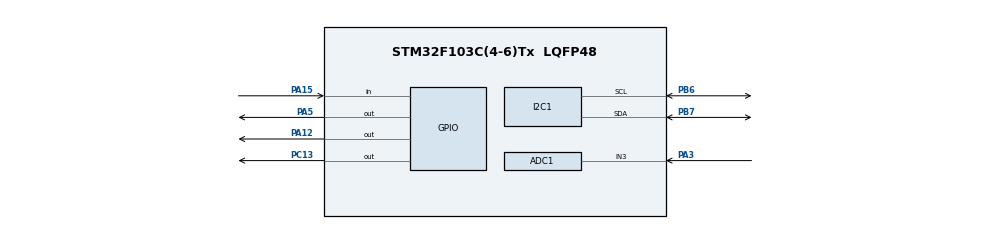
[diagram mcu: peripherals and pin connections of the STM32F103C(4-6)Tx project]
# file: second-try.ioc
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ADC1.Channel-1\#ChannelRegularConversion=ADC_CHANNEL_3
ADC1.NbrOfConversionFlag=1
ADC1.Rank-1\#ChannelRegularConversion=1
ADC1.SamplingTime-1\#ChannelRegularConversion=ADC_SAMPLETIME_1CYCLE_5
ADC1.master=1
Mcu.Family=STM32F1
Mcu.Name=STM32F103C(4-6)Tx
Mcu.Package=LQFP48
NVIC.PriorityGroup=NVIC_PRIORITYGROUP_4
PA12.Signal=GPIO_Output
PA13.Mode=Serial_Wire
PA13.Signal=SYS_JTMS-SWDIO
PA14.Mode=Serial_Wire
PA14.Signal=SYS_JTCK-SWCLK
PA15.Signal=GPIO_Input
PA3.Signal=ADCx_IN3
PA5.Signal=GPIO_Output
PB6.Mode=I2C
PB6.Signal=I2C1_SCL
PB7.Mode=I2C
PB7.Signal=I2C1_SDA
PC13-TAMPER-RTC.Signal=GPIO_Output
ProjectManager.HeapSize=0x200
ProjectManager.StackSize=0x400
ProjectManager.TargetToolchain=MDK-ARM V5.32
RCC.APB1Freq_Value=8000000
RCC.APB2Freq_Value=8000000
SH.ADCx_IN3.0=ADC1_IN3,IN3
TIM2.ClockDivision=TIM_CLOCKDIVISION_DIV1
TIM2.Prescaler=7
VP_TIM2_VS_ClockSourceINT.Mode=Internal
board=custom

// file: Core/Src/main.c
/* USER CODE BEGIN Header */
/**
  ******************************************************************************
  * @file           : main.c
  * @brief          : Main program body
  ******************************************************************************
  * @attention
  *
  * Copyright (c) 2026 STMicroelectronics.
  * All rights reserved.
  *
  * This software is licensed under terms that can be found in the LICENSE file
  * in the root directory of this software component.
  * If no LICENSE file comes with this software, it is provided AS-IS.
  *
  ******************************************************************************
  */
/* USER CODE END Header */
#include "main.h"
#include "oled.h"
#include "dht11.h"
#include "hcsr04.h"
#include <stdio.h>

ADC_HandleTypeDef hadc1;

I2C_HandleTypeDef hi2c1;

TIM_HandleTypeDef htim2;

void SystemClock_Config(void);
static void MX_GPIO_Init(void);
static void MX_I2C1_Init(void);
static void MX_TIM2_Init(void);
static void MX_ADC1_Init(void);

int main(void)
{

  /* MCU Configuration--------------------------------------------------------*/

  /* Reset of all peripherals, Initializes the Flash interface and the Systick. */
  HAL_Init();

  /* Configure the system clock */
  SystemClock_Config();

  /* Initialize all configured peripherals */
  MX_GPIO_Init();
  MX_I2C1_Init();
  MX_TIM2_Init();
  MX_ADC1_Init();
  /* USER CODE BEGIN 2 */
	HAL_TIM_Base_Start(&htim2);
	OLED_Init();

uint8_t temperature;
uint8_t humidity;
uint16_t distance;
char buffer[30];
uint32_t soil_value = 0;
uint32_t dryValue = 4000;
uint32_t wetValue = 1500;
uint8_t moisture = 0;
  /* USER CODE END 2 */

  /* Infinite loop */
  while (1)
  {
 distance = HCSR04_ReadDistance();

		if (DHT11_Read(&temperature, &humidity))
    {
        OLED_Clear();

        OLED_SetCursor(0, 0);
        sprintf(buffer, "Air Temp: %d C", temperature);
        OLED_WriteString(buffer);

        OLED_SetCursor(0, 2);
        sprintf(buffer, "Air Hum: %d %%", humidity);
        OLED_WriteString(buffer);

       // OLED_Update();
    }
    else
    {
        OLED_Clear();

        OLED_SetCursor(0, 0);
        OLED_WriteString("still working...");

        OLED_Update();
    }

		   OLED_SetCursor(0, 4);

    if (distance == 0)
    {
        OLED_WriteString("water till sensor");
    }else if(distance>=13){

			OLED_WriteString("No water");
    }else
    {
			uint16_t c=13-distance;
        sprintf(buffer, "water level: %d cm", c);
        OLED_WriteString(buffer);
    }

		 HAL_ADC_Start(&hadc1);

    HAL_ADC_PollForConversion(&hadc1, 100);

    soil_value = HAL_ADC_GetValue(&hadc1);

		if (soil_value >= dryValue)
{
    moisture = 0;
}
else if (soil_value <= wetValue)
{
    moisture = 100;
}
else
{
    moisture = ((dryValue - soil_value) * 100) /
               (dryValue - wetValue);
}

    HAL_ADC_Stop(&hadc1);
 OLED_SetCursor(0, 6);
		 sprintf(buffer, "soil moist: %d %%", moisture);
        OLED_WriteString(buffer);

		OLED_Update();

    HAL_Delay(500);

  }
}

void SystemClock_Config(void)
{
  RCC_OscInitTypeDef RCC_OscInitStruct = {0};
  RCC_ClkInitTypeDef RCC_ClkInitStruct = {0};
  RCC_PeriphCLKInitTypeDef PeriphClkInit = {0};

  /** Initializes the RCC Oscillators according to the specified parameters
  * in the RCC_OscInitTypeDef structure.
  */
  RCC_OscInitStruct.OscillatorType = RCC_OSCILLATORTYPE_HSI;
  RCC_OscInitStruct.HSIState = RCC_HSI_ON;
  RCC_OscInitStruct.HSICalibrationValue = RCC_HSICALIBRATION_DEFAULT;
  RCC_OscInitStruct.PLL.PLLState = RCC_PLL_NONE;
  if (HAL_RCC_OscConfig(&RCC_OscInitStruct) != HAL_OK)
  {
    Error_Handler();
  }

  /** Initializes the CPU, AHB and APB buses clocks
  */
  RCC_ClkInitStruct.ClockType = RCC_CLOCKTYPE_HCLK|RCC_CLOCKTYPE_SYSCLK
                              |RCC_CLOCKTYPE_PCLK1|RCC_CLOCKTYPE_PCLK2;
  RCC_ClkInitStruct.SYSCLKSource = RCC_SYSCLKSOURCE_HSI;
  RCC_ClkInitStruct.AHBCLKDivider = RCC_SYSCLK_DIV1;
  RCC_ClkInitStruct.APB1CLKDivider = RCC_HCLK_DIV1;
  RCC_ClkInitStruct.APB2CLKDivider = RCC_HCLK_DIV1;

  if (HAL_RCC_ClockConfig(&RCC_ClkInitStruct, FLASH_LATENCY_0) != HAL_OK)
  {
    Error_Handler();
  }
  PeriphClkInit.PeriphClockSelection = RCC_PERIPHCLK_ADC;
  PeriphClkInit.AdcClockSelection = RCC_ADCPCLK2_DIV2;
  if (HAL_RCCEx_PeriphCLKConfig(&PeriphClkInit) != HAL_OK)
  {
    Error_Handler();
  }
}

static void MX_ADC1_Init(void)
{

  ADC_ChannelConfTypeDef sConfig = {0};

  /** Common config
  */
  hadc1.Instance = ADC1;
  hadc1.Init.ScanConvMode = ADC_SCAN_DISABLE;
  hadc1.Init.ContinuousConvMode = DISABLE;
  hadc1.Init.DiscontinuousConvMode = DISABLE;
  hadc1.Init.ExternalTrigConv = ADC_SOFTWARE_START;
  hadc1.Init.DataAlign = ADC_DATAALIGN_RIGHT;
  hadc1.Init.NbrOfConversion = 1;
  if (HAL_ADC_Init(&hadc1) != HAL_OK)
  {
    Error_Handler();
  }

  /** Configure Regular Channel
  */
  sConfig.Channel = ADC_CHANNEL_3;
  sConfig.Rank = ADC_REGULAR_RANK_1;
  sConfig.SamplingTime = ADC_SAMPLETIME_1CYCLE_5;
  if (HAL_ADC_ConfigChannel(&hadc1, &sConfig) != HAL_OK)
  {
    Error_Handler();
  }

}

static void MX_I2C1_Init(void)
{

  hi2c1.Instance = I2C1;
  hi2c1.Init.ClockSpeed = 100000;
  hi2c1.Init.DutyCycle = I2C_DUTYCYCLE_2;
  hi2c1.Init.OwnAddress1 = 0;
  hi2c1.Init.AddressingMode = I2C_ADDRESSINGMODE_7BIT;
  hi2c1.Init.DualAddressMode = I2C_DUALADDRESS_DISABLE;
  hi2c1.Init.OwnAddress2 = 0;
  hi2c1.Init.GeneralCallMode = I2C_GENERALCALL_DISABLE;
  hi2c1.Init.NoStretchMode = I2C_NOSTRETCH_DISABLE;
  if (HAL_I2C_Init(&hi2c1) != HAL_OK)
  {
    Error_Handler();
  }

}

static void MX_TIM2_Init(void)
{

  TIM_ClockConfigTypeDef sClockSourceConfig = {0};
  TIM_MasterConfigTypeDef sMasterConfig = {0};

  htim2.Instance = TIM2;
  htim2.Init.Prescaler = 7;
  htim2.Init.CounterMode = TIM_COUNTERMODE_UP;
  htim2.Init.Period = 65535;
  htim2.Init.ClockDivision = TIM_CLOCKDIVISION_DIV1;
  htim2.Init.AutoReloadPreload = TIM_AUTORELOAD_PRELOAD_DISABLE;
  if (HAL_TIM_Base_Init(&htim2) != HAL_OK)
  {
    Error_Handler();
  }
  sClockSourceConfig.ClockSource = TIM_CLOCKSOURCE_INTERNAL;
  if (HAL_TIM_ConfigClockSource(&htim2, &sClockSourceConfig) != HAL_OK)
  {
    Error_Handler();
  }
  sMasterConfig.MasterOutputTrigger = TIM_TRGO_RESET;
  sMasterConfig.MasterSlaveMode = TIM_MASTERSLAVEMODE_DISABLE;
  if (HAL_TIMEx_MasterConfigSynchronization(&htim2, &sMasterConfig) != HAL_OK)
  {
    Error_Handler();
  }

}

static void MX_GPIO_Init(void)
{
  GPIO_InitTypeDef GPIO_InitStruct = {0};

  /* GPIO Ports Clock Enable */
  __HAL_RCC_GPIOC_CLK_ENABLE();
  __HAL_RCC_GPIOA_CLK_ENABLE();
  __HAL_RCC_GPIOB_CLK_ENABLE();

  /*Configure GPIO pin Output Level */
  HAL_GPIO_WritePin(GPIOC, GPIO_PIN_13, GPIO_PIN_RESET);

  /*Configure GPIO pin Output Level */
  HAL_GPIO_WritePin(GPIOA, GPIO_PIN_5|GPIO_PIN_12, GPIO_PIN_RESET);

  /*Configure GPIO pin : PC13 */
  GPIO_InitStruct.Pin = GPIO_PIN_13;
  GPIO_InitStruct.Mode = GPIO_MODE_OUTPUT_PP;
  GPIO_InitStruct.Pull = GPIO_NOPULL;
  GPIO_InitStruct.Speed = GPIO_SPEED_FREQ_LOW;
  HAL_GPIO_Init(GPIOC, &GPIO_InitStruct);

  /*Configure GPIO pins : PA5 PA12 */
  GPIO_InitStruct.Pin = GPIO_PIN_5|GPIO_PIN_12;
  GPIO_InitStruct.Mode = GPIO_MODE_OUTPUT_PP;
  GPIO_InitStruct.Pull = GPIO_NOPULL;
  GPIO_InitStruct.Speed = GPIO_SPEED_FREQ_LOW;
  HAL_GPIO_Init(GPIOA, &GPIO_InitStruct);

  /*Configure GPIO pin : PA15 */
  GPIO_InitStruct.Pin = GPIO_PIN_15;
  GPIO_InitStruct.Mode = GPIO_MODE_INPUT;
  GPIO_InitStruct.Pull = GPIO_NOPULL;
  HAL_GPIO_Init(GPIOA, &GPIO_InitStruct);

}

void Error_Handler(void)
{
  __disable_irq();
  while (1)
  {
  }
}
